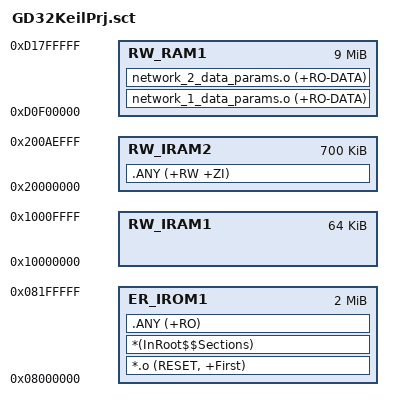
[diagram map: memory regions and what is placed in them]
; *************************************************************
; *** Scatter-Loading Description File generated by uVision ***
; *************************************************************

LR_IROM1 0x08000000 0x00200000  {    ; load region size_region
  ER_IROM1 0x08000000 0x00200000  {  ; load address = execution address
   *.o (RESET, +First)
   *(InRoot$$Sections)
   .ANY (+RO)
  }
  RW_IRAM1 0x10000000 0x00010000  {  ; RW data
   ;.ANY (+RW +ZI)
   ;network_1.o(+RW +ZI)
   ;network_2.o(+RW +ZI)
   ;*NetworkRuntime801_CM4_Keil.lib*(+RO)
   ;network_1_data_params.o
   ;.ANY(CCMRAM)
  }
  RW_RAM1 0xD0F00000 0x900000  {
  network_1_data_params.o (+RO-DATA)
  network_2_data_params.o (+RO-DATA)
  ;.ANY (+RW +ZI)
  ;main.o(+RW +ZI)
  }
  RW_IRAM2 0x20000000 0x000AF000  {
  ;network_1_data_params.o (+RO-DATA)
  ;network_2_data_params.o (+RO-DATA)
  .ANY (+RW +ZI)
  }
  

}

